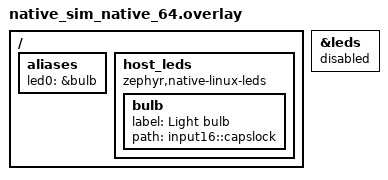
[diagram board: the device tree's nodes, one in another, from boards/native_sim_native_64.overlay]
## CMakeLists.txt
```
#-------------------------------------------------------------------------------
# ZMatter - Matter light bulb on Zephyr
#
# Copyright (c) 2021 Nordic Semiconductor ASA
# SPDX-License-Identifier: Apache-2.0

cmake_minimum_required(VERSION 3.20.0)

# Matter (connectedhomeip) is fetched by west into modules/lib/connectedhomeip.
# Its Zephyr module lives in a sub-directory, so it has to be registered
# explicitly before Zephyr is loaded.
if(NOT DEFINED CHIP_ROOT)
  get_filename_component(CHIP_ROOT $ENV{ZEPHYR_BASE}/../modules/lib/connectedhomeip ABSOLUTE)
endif()
list(APPEND EXTRA_ZEPHYR_MODULES ${CHIP_ROOT}/config/zephyr/chip-module)

# Normally generated by the Matter bootstrap (scripts/activate.sh). It is only
# needed for pigweed's clang toolchain, so an empty file is enough here.
if(NOT EXISTS ${CHIP_ROOT}/build_overrides/pigweed_environment.gni)
  file(WRITE ${CHIP_ROOT}/build_overrides/pigweed_environment.gni "")
endif()

find_package(Zephyr REQUIRED HINTS $ENV{ZEPHYR_BASE})

project(app LANGUAGES C CXX)

# libCHIP.a uses kernel APIs (e.g. k_timer) and is placed after the kernel
# library on the link line; append the kernel archive again after it.
target_link_libraries(chip INTERFACE $<TARGET_FILE:kernel>)

# Application code is C
target_sources(app PRIVATE
  src/main.c
  src/light.c
)
target_sources_ifdef(CONFIG_WIFI_CREDENTIALS_CONNECT_STORED app PRIVATE src/wifi.c)

# C++ shim exposing the Matter C++ API to the C application (src/matter/matter.h)
target_sources(app PRIVATE
  src/matter/matter.cpp
  src/matter/network.cpp
)
target_include_directories(app PRIVATE src)

include(${CHIP_ROOT}/src/app/chip_data_model.cmake)

chip_configure_data_model(app
  ZAP_FILE ${CMAKE_CURRENT_SOURCE_DIR}/light.zap
  ZCL_PATH ${CHIP_ROOT}/src/app/zap-templates/zcl/zcl.json
)

# The code below locates the git index file for this repository and adds it as a dependency for
# the application VERSION file so that if the repo has a new commit added, even if no files in
# the build have changed, the application version file will be regenerated with the new git commit
find_package(Git QUIET)
if(GIT_FOUND)
  execute_process(
    COMMAND ${GIT_EXECUTABLE} rev-parse --absolute-git-dir
    WORKING_DIRECTORY .
    OUTPUT_VARIABLE application_git_dir
    OUTPUT_STRIP_TRAILING_WHITESPACE
    ERROR_STRIP_TRAILING_WHITESPACE
    ERROR_VARIABLE stderr
    RESULT_VARIABLE return_code
  )
  # If there is an error e.g. it is not a git repo, we just silently ignore it and continue
  # without a dependency, this will be the case with freestanding applications.
  if(NOT return_code)
    if(NOT "${stderr}" STREQUAL "")
      message(WARNING "Application build version git rev-parse warned: ${stderr}")
    endif()

    set_property(TARGET app_version_h PROPERTY APP_VERSION_DEPENDS ${application_git_dir}/index)
  endif()
endif()
```

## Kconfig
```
# Copyright (c) 2021 Nordic Semiconductor ASA
# SPDX-License-Identifier: Apache-2.0
#
# This file is the application Kconfig entry point. All application Kconfig
# options can be defined here or included via other application Kconfig files.
# You can browse these options using the west targets menuconfig (terminal) or
# guiconfig (GUI).

menu "Zephyr"
source "Kconfig.zephyr"
endmenu

module = APP
module-str = APP
source "subsys/logging/Kconfig.template.log_config"

if CHIP

# Matter only defines the software version options when the application has
# no VERSION file, so provide them here based on app/VERSION.
config CHIP_DEVICE_SOFTWARE_VERSION
	int "Software version"
	default 1
	range 0 4294967295
	help
	  32-bit software version number exposed in the Basic Information cluster.

config CHIP_DEVICE_SOFTWARE_VERSION_STRING
	string "Software version string"
	default "$(APPVERSION)"
	help
	  Human-readable software version exposed in the Basic Information cluster.

endif # CHIP
```

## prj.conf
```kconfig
# Copyright (c) 2021 Nordic Semiconductor ASA
# SPDX-License-Identifier: Apache-2.0
#
# Matter on/off light bulb for native_sim. Matter runs over the host's
# network interfaces (see README).

# C17 for the application, C++17 for Matter and its wrapper (src/matter)
CONFIG_STD_C17=y
CONFIG_CPP=y
CONFIG_STD_CPP17=y

# Kernel
CONFIG_MAIN_STACK_SIZE=8192
CONFIG_SYSTEM_WORKQUEUE_STACK_SIZE=4096
CONFIG_HEAP_MEM_POOL_SIZE=65536
CONFIG_COMMON_LIBC_MALLOC_ARENA_SIZE=36864
CONFIG_INIT_STACKS=y

# Networking: Zephyr IP stack over the ESP32 Wi-Fi station
# Network Configuration
CONFIG_NETWORKING=y
CONFIG_NET_IPV6=y
CONFIG_NET_IPV6_MLD=y
CONFIG_NET_IPV6_ND=y
CONFIG_NET_IPV6_DAD=y
CONFIG_NET_IPV4=y
CONFIG_NET_DHCPV4=y
CONFIG_NET_UDP=y
CONFIG_NET_SOCKETS=y

CONFIG_NET_IF_UNICAST_IPV6_ADDR_COUNT=6
CONFIG_NET_IF_MCAST_IPV6_ADDR_COUNT=14
CONFIG_NET_MAX_CONTEXTS=10
CONFIG_ZVFS_OPEN_MAX=16

# Wi-Fi statistics, reported by the Matter Wi-Fi diagnostics cluster
CONFIG_NET_STATISTICS=y
CONFIG_NET_STATISTICS_USER_API=y

# Wi-Fi management
CONFIG_NET_MGMT=y
CONFIG_NET_MGMT_EVENT=y
CONFIG_NET_MGMT_EVENT_QUEUE_SIZE=16
CONFIG_NET_MGMT_EVENT_STACK_SIZE=4096

# Wi-Fi Configuration
CONFIG_WIFI=y
CONFIG_WIFI_NM=y

# Bluetooth LE commissioning: the commissioner sends the Wi-Fi credentials
# over BLE, and the device then joins Wi-Fi.
CONFIG_BT=y
CONFIG_BT_PERIPHERAL=y
CONFIG_BT_DEVICE_NAME="ZMatter"
CONFIG_BT_DEVICE_NAME_DYNAMIC=y
CONFIG_BT_DEVICE_NAME_MAX=15
CONFIG_BT_MAX_CONN=1
CONFIG_BT_GATT_DYNAMIC_DB=y
CONFIG_BT_GATT_CACHING=n
# No pairing or bonding: a new random static address is used on every boot
CONFIG_BT_BONDABLE=n
CONFIG_BT_SETTINGS=n

# Large ATT MTU for the Matter BLE transport (BTP)
CONFIG_BT_L2CAP_TX_MTU=247
CONFIG_BT_BUF_ACL_RX_SIZE=251
CONFIG_BT_BUF_ACL_TX_SIZE=251
CONFIG_BT_RX_STACK_SIZE=2048

# Fast connection parameter updates: some commissioners switch to IP quickly
CONFIG_BT_PERIPHERAL_PREF_MIN_INT=36
CONFIG_BT_PERIPHERAL_PREF_MAX_INT=36
CONFIG_BT_PERIPHERAL_PREF_TIMEOUT=500
CONFIG_BT_CONN_PARAM_UPDATE_TIMEOUT=1000

# Enable LED drivers
CONFIG_LED=y

# Persistent storage (backed by the simulated flash, flash.bin)
CONFIG_FLASH=y
CONFIG_FLASH_MAP=y
CONFIG_NVS=y
CONFIG_SETTINGS=y
CONFIG_SETTINGS_NVS=y

# Crypto: PSA API from TF-PSA-Crypto, X.509 from Mbed TLS
CONFIG_MBEDTLS=y
CONFIG_PSA_CRYPTO=y
CONFIG_MBEDTLS_MD_C=y
CONFIG_MBEDTLS_ENTROPY_C=y
CONFIG_MBEDTLS_CTR_DRBG_C=y
CONFIG_ENTROPY_GENERATOR=y

# Matter
CONFIG_CHIP=y
CONFIG_CHIP_WIFI=y
CONFIG_CHIP_ENABLE_PAIRING_AUTOSTART=y
CONFIG_CHIP_CRYPTO_PSA=y
CONFIG_CHIP_OTA_REQUESTOR=n
CONFIG_CHIP_DEVICE_PRODUCT_NAME="ZMatter Light"
CONFIG_CHIP_DEVICE_TYPE=256
CONFIG_CHIP_PROJECT_CONFIG="src/CHIPProjectConfig.h"
CONFIG_OPENTHREAD=n
CONFIG_NET_L2_OPENTHREAD=n
CONFIG_MCUMGR=n
```

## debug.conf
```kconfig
# Copyright (c) 2021 Nordic Semiconductor ASA
# SPDX-License-Identifier: Apache-2.0
#
# This is a Kconfig fragment which can be used to enable debug-related options
# in the application. See the README for more details.

# Logging
CONFIG_LOG=y
CONFIG_NET_LOG=y
CONFIG_LOG_BUFFER_SIZE=8192
CONFIG_LOG_PROCESS_THREAD_STACK_SIZE=4096
CONFIG_LOG_MODE_DEFERRED=y

CONFIG_NET_LOG=y
CONFIG_MATTER_LOG_LEVEL_WRN=y

# Thread stack usage, reported by the Matter diagnostics clusters
CONFIG_THREAD_STACK_INFO=y
CONFIG_STACK_SENTINEL=y
CONFIG_THREAD_ANALYZER=y
CONFIG_THREAD_ANALYZER_AUTO=y
```

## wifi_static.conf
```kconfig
# Copyright (c) 2026 Muhammad Waleed Badar
# SPDX-License-Identifier: Apache-2.0
#
# Join a fixed Wi-Fi network at boot instead of receiving the credentials
# over Bluetooth LE during commissioning. The device is then commissioned
# on-network. Pass the credentials at build time (see README):
#   -DEXTRA_CONF_FILE=wifi_static.conf
#   -DCONFIG_WIFI_CREDENTIALS_STATIC_SSID=\"<ssid>\"
#   -DCONFIG_WIFI_CREDENTIALS_STATIC_PASSWORD=\"<password>\"

# Wi-Fi credentials, connected automatically at boot
CONFIG_WIFI_CREDENTIALS=y
CONFIG_WIFI_CREDENTIALS_STATIC=y
CONFIG_WIFI_CREDENTIALS_BACKEND_SETTINGS=y
CONFIG_WIFI_CREDENTIALS_CONNECT_STORED=y

# No Bluetooth LE commissioning
CONFIG_BT=n
```

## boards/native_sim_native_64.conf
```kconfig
# Copyright (c) 2026 Muhammad Waleed Badar
# SPDX-License-Identifier: Apache-2.0
#
# On native_sim Matter uses the host's sockets directly, so the Zephyr IP
# stack, Wi-Fi and Bluetooth LE from prj.conf are not needed.

# Matter over the host network instead of Wi-Fi
CONFIG_CHIP_ETHERNET=y
CONFIG_CHIP_WIFI=n

# Networking: disables the IP stack, sockets, net_mgmt and net statistics
CONFIG_NETWORKING=n

# Wi-Fi
CONFIG_WIFI=n
CONFIG_WIFI_NM=n

# No Bluetooth controller: commissioned on-network
CONFIG_BT=n
```

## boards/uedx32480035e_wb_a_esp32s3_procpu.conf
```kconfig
# Copyright (c) 2026 Muhammad Waleed Badar
# SPDX-License-Identifier: Apache-2.0
#
# VIEWE UEDX32480035E-WB-A: Matter over Wi-Fi, WS2812 RGB LED as the bulb.
# Wi-Fi and Bluetooth LE are configured in prj.conf and socs/esp32s3_procpu.conf.

# Light bulb: WS2812 RGB LED
CONFIG_LED=n
CONFIG_LED_STRIP=y
```

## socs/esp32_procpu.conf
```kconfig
# Copyright (c) 2026 Muhammad Waleed Badar
# SPDX-License-Identifier: Apache-2.0

# ESP32 related configs
CONFIG_ESP32_WIFI_TASK_STACK_SIZE=4096

# The ESP32 has much less internal RAM than the ESP32-S3: Matter, Wi-Fi and
# Bluetooth LE only fit with smaller heaps and buffer pools (Matter pools: see
# src/CHIPProjectConfig.h).

# Kernel heap, used by the Wi-Fi and Bluetooth controller drivers. The
# drivers ask for 80 KB by default, sized for larger buffer pools.
CONFIG_HEAP_MEM_POOL_IGNORE_MIN=y
CONFIG_HEAP_MEM_POOL_SIZE=40960

# Wi-Fi buffers, allocated from the kernel heap
CONFIG_ESP32_WIFI_STATIC_RX_BUFFER_NUM=6
CONFIG_ESP32_WIFI_DYNAMIC_RX_BUFFER_NUM=16
CONFIG_ESP32_WIFI_DYNAMIC_TX_BUFFER_NUM=16
CONFIG_ESP32_WIFI_AMPDU_TX_ENABLED=n

# IP stack: Matter only uses IPv6
CONFIG_NET_IPV4=n
CONFIG_NET_DHCPV4=n
CONFIG_NET_MAX_CONTEXTS=6
CONFIG_NET_PKT_RX_COUNT=8
CONFIG_NET_PKT_TX_COUNT=8
CONFIG_NET_BUF_RX_COUNT=24
CONFIG_NET_BUF_TX_COUNT=24

# Bluetooth host buffers
CONFIG_BT_BUF_EVT_RX_COUNT=10
CONFIG_BT_BUF_ACL_TX_COUNT=4

# AES lookup tables in flash instead of 8 KB of RAM
CONFIG_MBEDTLS_AES_ROM_TABLES=y
```

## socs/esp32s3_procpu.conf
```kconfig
# Copyright (c) 2026 Muhammad Waleed Badar
# SPDX-License-Identifier: Apache-2.0

# ESP32-S3 related configs
CONFIG_ESP32_WIFI_TASK_STACK_SIZE=4096
```

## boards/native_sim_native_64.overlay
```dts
/*
 * Copyright (c) 2026 Muhammad Waleed Badar
 * SPDX-License-Identifier: Apache-2.0
 *
 * The light bulb is a real LED of the host, driven through
 * /sys/class/leds/<path>/brightness. List the available LEDs with
 * `ls /sys/class/leds` and set `path` accordingly.
 */

/ {
	aliases {
		led0 = &bulb;
	};

	host_leds {
		compatible = "zephyr,native-linux-leds";

		bulb: bulb {
			label = "Light bulb";
			path = "input16::capslock";
		};
	};
};

/* Replaced by the host LED above. */
&leds {
	status = "disabled";
};
```

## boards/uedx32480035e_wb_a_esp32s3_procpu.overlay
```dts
/*
 * Copyright (c) 2026 Muhammad Waleed Badar
 * SPDX-License-Identifier: Apache-2.0
 *
 * VIEWE UEDX32480035E-WB-A: the light bulb is the on-board WS2812 RGB LED
 * (rgb_led, alias led-strip). Matter runs over Wi-Fi.
 */

/ {
	aliases {
		bulb-strip = &rgb_led;
	};
};

&sdhc0 {
	status = "disabled";
};
```

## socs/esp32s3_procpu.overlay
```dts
/*
 * Copyright (c) 2026 Muhammad Waleed Badar
 * SPDX-License-Identifier: Apache-2.0
 */

/ {
	chosen {
		/* Matter state (fabrics, attributes) is kept in the settings */
		zephyr,settings-partition = &storage_partition;
	};
};
```

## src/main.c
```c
/*
 * Copyright (c) 2026 Muhammad Waleed Badar
 * SPDX-License-Identifier: Apache-2.0
 */

#include "light.h"
#include "matter/matter.h"
#include "wifi.h"

#include <zephyr/logging/log.h>

LOG_MODULE_REGISTER(app, CONFIG_APP_LOG_LEVEL);

int main(void)
{
	int err = light_init();

	if (err != 0) {
		LOG_ERR("Light init failed: %d", err);
		return err;
	}

	err = matter_init();
	if (err != 0) {
		return err;
	}

#ifdef CONFIG_WIFI_CREDENTIALS_CONNECT_STORED
	err = wifi_init();
	if (err != 0) {
		return err;
	}
#endif

	LOG_INF("ZMatter light bulb ready (endpoint %u)", LIGHT_ENDPOINT_ID);

	return 0;
}
```

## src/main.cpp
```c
/*
 * Copyright (c) 2026 Muhammad Waleed Badar
 * SPDX-License-Identifier: Apache-2.0
 */

#include "light.h"
#include "wifi.h"

#include <app/server/Server.h>
#include <credentials/DeviceAttestationCredsProvider.h>
#include <credentials/examples/DeviceAttestationCredsExample.h>
#include <data-model-providers/codegen/Instance.h>
#include <lib/support/CHIPMem.h>
#include <platform/CHIPDeviceLayer.h>
#include <platform/Zephyr/DeviceInstanceInfoProviderImpl.h>
#include <setup_payload/OnboardingCodesUtil.h>

#include <zephyr/kernel.h>
#include <zephyr/logging/log.h>

LOG_MODULE_REGISTER(app, CONFIG_APP_LOG_LEVEL);

using namespace chip;
using namespace chip::DeviceLayer;

namespace {

void ChipEventHandler(const ChipDeviceEvent *event, intptr_t /* arg */)
{
	switch (event->Type) {
	case DeviceEventType::kCommissioningComplete:
		LOG_INF("Commissioning complete");
		break;
	case DeviceEventType::kInterfaceIpAddressChanged:
		LOG_INF("IP address changed");
		break;
	default:
		break;
	}
}

#define RETURN_ON_ERROR(expr)                                                                      \
	do {                                                                                       \
		CHIP_ERROR __err = (expr);                                                         \
		if (__err != CHIP_NO_ERROR) {                                                      \
			LOG_ERR("%s failed: %" CHIP_ERROR_FORMAT, #expr, __err.Format());         \
			return __err;                                                              \
		}                                                                                  \
	} while (0)

CHIP_ERROR InitMatter()
{
	RETURN_ON_ERROR(Platform::MemoryInit());
	RETURN_ON_ERROR(PlatformMgr().InitChipStack());

	/* Development credentials only: test DAC and test setup payload. */
	SetDeviceInstanceInfoProvider(&DeviceInstanceInfoProviderMgrImpl());
	Credentials::SetDeviceAttestationCredentialsProvider(
		Credentials::Examples::GetExampleDACProvider());

	static CommonCaseDeviceServerInitParams initParams;
	RETURN_ON_ERROR(initParams.InitializeStaticResourcesBeforeServerInit());
	initParams.dataModelProvider =
		app::CodegenDataModelProviderInstance(initParams.persistentStorageDelegate);
	RETURN_ON_ERROR(Server::GetInstance().Init(initParams));

	ConfigurationMgr().LogDeviceConfig();
	PrintOnboardingCodes(RendezvousInformationFlags(RendezvousInformationFlag::kOnNetwork));

	RETURN_ON_ERROR(PlatformMgr().AddEventHandler(ChipEventHandler, 0));
	RETURN_ON_ERROR(PlatformMgr().StartEventLoopTask());

	return CHIP_NO_ERROR;
}

} // namespace

int main(void)
{
	int err = LightInit();

	if (err) {
		LOG_ERR("Light init failed: %d", err);
		return err;
	}

	if (InitMatter() != CHIP_NO_ERROR) {
		return -1;
	}

#ifdef CONFIG_WIFI_CREDENTIALS_CONNECT_STORED
	if (WifiInit() != 0) {
		return -1;
	}
#endif

	LOG_INF("ZMatter light bulb ready (endpoint %u)", kLightEndpointId);

	return 0;
}
```

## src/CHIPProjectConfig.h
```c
/*
 * Copyright (c) 2026 Muhammad Waleed Badar
 * SPDX-License-Identifier: Apache-2.0
 *
 * Matter project configuration overrides, applied to both the application
 * and the Matter libraries.
 */

#pragma once

/*
 * On native_sim (CONFIG_ARCH_POSIX) Matter talks to the network through the
 * host's BSD sockets, so enumerate the host's interfaces as well instead of
 * the Zephyr ones and join multicast groups with regular socket options.
 */
#ifdef CONFIG_ARCH_POSIX
#define CHIP_SYSTEM_CONFIG_USE_ZEPHYR_NET_IF          0
#define CHIP_SYSTEM_CONFIG_USE_BSD_IFADDRS            1
#define CHIP_SYSTEM_CONFIG_USE_PLATFORM_MULTICAST_API 0
#define IPV6_MULTICAST_IMPLEMENTED

/* Minimal mDNS opens an endpoint per host interface (docker, VPN, ...). */
#define INET_CONFIG_NUM_UDP_ENDPOINTS 32
#endif

/*
 * The ESP32 has much less internal RAM than the ESP32-S3: smaller Matter
 * pools so that Matter, Wi-Fi and Bluetooth LE fit (see
 * socs/esp32_procpu.conf). Three fabrics is below the five that Matter
 * certification requires, which is fine for development.
 */
#ifdef CONFIG_SOC_SERIES_ESP32
#define CHIP_SYSTEM_CONFIG_PACKETBUFFER_POOL_SIZE 6
#define CHIP_CONFIG_MAX_FABRICS                   3
#define CHIP_CONFIG_SECURE_SESSION_POOL_SIZE      8
#define CHIP_CONFIG_MAX_GROUP_DATA_PEERS          4

/*
 * Set along with the default CHIP_CONFIG_MAX_FABRICS in
 * platform/Zephyr/CHIPPlatformConfig.h, so skipped once it is overridden.
 */
#define INET_CONFIG_UDP_SOCKET_MREQN                    1
#define CHIP_SYSTEM_CONFIG_USE_ZEPHYR_SOCKET_EXTENSIONS 0
#endif
```

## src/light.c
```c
/*
 * Copyright (c) 2026 Muhammad Waleed Badar
 * SPDX-License-Identifier: Apache-2.0
 */

#include "light.h"

#include <errno.h>

#include <zephyr/logging/log.h>
#include <zephyr/sys/util.h>

LOG_MODULE_DECLARE(app, CONFIG_APP_LOG_LEVEL);

static bool led_ready;

#if DT_NODE_EXISTS(DT_ALIAS(bulb_strip))

#include <zephyr/drivers/led_strip.h>

/*
 * The bulb: an RGB LED strip (alias bulb-strip), lit white when on, e.g.
 * the WS2812 LED of boards/uedx32480035e_wb_a_esp32s3_procpu.overlay.
 */
static const struct device *const strip = DEVICE_DT_GET(DT_ALIAS(bulb_strip));
static struct led_rgb pixels[DT_PROP(DT_ALIAS(bulb_strip), chain_length)];

/* Full brightness is uncomfortably bright on a bare WS2812. */
#define BULB_LEVEL 0x40U

static int led_write(bool on)
{
	for (size_t i = 0; i < ARRAY_SIZE(pixels); i++) {
		uint8_t level = on ? BULB_LEVEL : 0U;

		pixels[i].r = level;
		pixels[i].g = level;
		pixels[i].b = level;
	}

	return led_strip_update_rgb(strip, pixels, ARRAY_SIZE(pixels));
}

static const char *led_name(void)
{
	return strip->name;
}

static bool led_is_ready(void)
{
	return device_is_ready(strip);
}

#elif DT_NODE_EXISTS(DT_ALIAS(led0))

#include <zephyr/drivers/led.h>

/* The bulb: led0 (on native_sim a host LED, see boards/native_sim_native_64.overlay). */
static const struct led_dt_spec led = LED_DT_SPEC_GET(DT_ALIAS(led0));

static int led_write(bool on)
{
	return on ? led_on_dt(&led) : led_off_dt(&led);
}

static const char *led_name(void)
{
	return led.dev->name;
}

static bool led_is_ready(void)
{
	return led_is_ready_dt(&led);
}

#else

/* No bulb on this board (e.g. esp32_devkitc): the light state is only logged. */
static int led_write(bool on)
{
	ARG_UNUSED(on);

	return -ENODEV;
}

static const char *led_name(void)
{
	return "(none)";
}

static bool led_is_ready(void)
{
	return false;
}

#endif

int light_init(void)
{
	if (!led_is_ready()) {
		/* On native_sim this usually means no write access to the host LED. */
		LOG_WRN("LED %s is not ready, the light state is only logged", led_name());
		return 0;
	}

	led_ready = true;

	return led_write(false);
}

void light_set(bool on)
{
	if (led_ready) {
		int err = led_write(on);

		if (err != 0) {
			LOG_ERR("Failed to set LED: %d", err);
		}
	}

	LOG_INF("Light is %s", on ? "ON" : "OFF");
}
```

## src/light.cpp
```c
/*
 * Copyright (c) 2026 Muhammad Waleed Badar
 * SPDX-License-Identifier: Apache-2.0
 */

#include "light.h"

#include <app-common/zap-generated/attributes/Accessors.h>
#include <app-common/zap-generated/ids/Attributes.h>
#include <app-common/zap-generated/ids/Clusters.h>
#include <app/ConcreteAttributePath.h>
#include <app/util/generic-callbacks.h>

#include <zephyr/logging/log.h>

LOG_MODULE_DECLARE(app, CONFIG_APP_LOG_LEVEL);

using namespace chip;
using namespace chip::app::Clusters;

static bool sLedReady;

#if DT_NODE_EXISTS(DT_ALIAS(bulb_strip))

#include <zephyr/drivers/led_strip.h>

/*
 * The bulb: an RGB LED strip (alias bulb-strip), lit white when on, e.g.
 * the WS2812 LED of boards/uedx32480035e_wb_a_esp32s3_procpu.overlay.
 */
static const struct device *const sStrip = DEVICE_DT_GET(DT_ALIAS(bulb_strip));
static struct led_rgb sPixels[DT_PROP(DT_ALIAS(bulb_strip), chain_length)];

/* Full brightness is uncomfortably bright on a bare WS2812. */
#define BULB_LEVEL 0x40

static int LedWrite(bool on)
{
	for (struct led_rgb &pixel : sPixels) {
		pixel.r = pixel.g = pixel.b = on ? BULB_LEVEL : 0;
	}

	return led_strip_update_rgb(sStrip, sPixels, ARRAY_SIZE(sPixels));
}

static const char *LedName(void)
{
	return sStrip->name;
}

static bool LedIsReady(void)
{
	return device_is_ready(sStrip);
}

#else

#include <zephyr/drivers/led.h>

/* The bulb: led0 (on native_sim a host LED, see boards/native_sim_native_64.overlay). */
static const struct led_dt_spec sLed = LED_DT_SPEC_GET(DT_ALIAS(led0));

static int LedWrite(bool on)
{
	return on ? led_on_dt(&sLed) : led_off_dt(&sLed);
}

static const char *LedName(void)
{
	return sLed.dev->name;
}

static bool LedIsReady(void)
{
	return led_is_ready_dt(&sLed);
}

#endif

int LightInit(void)
{
	if (!LedIsReady()) {
		/* On native_sim this usually means no write access to the host LED. */
		LOG_WRN("LED %s is not ready, the light state is only logged", LedName());
		return 0;
	}

	sLedReady = true;

	return LedWrite(false);
}

static void LightSet(bool on)
{
	if (sLedReady) {
		int err = LedWrite(on);

		if (err) {
			LOG_ERR("Failed to set LED: %d", err);
		}
	}

	LOG_INF("Light is %s", on ? "ON" : "OFF");
}

void MatterPostAttributeChangeCallback(const app::ConcreteAttributePath &path, uint8_t type,
				       uint16_t size, uint8_t *value)
{
	if (path.mEndpointId == kLightEndpointId && path.mClusterId == OnOff::Id &&
	    path.mAttributeId == OnOff::Attributes::OnOff::Id) {
		LightSet(*value != 0);
	}
}

/* Restore the light from the persisted OnOff attribute at boot. */
void emberAfOnOffClusterInitCallback(EndpointId endpoint)
{
	bool on = false;

	if (endpoint != kLightEndpointId) {
		return;
	}

	if (OnOff::Attributes::OnOff::Get(endpoint, &on) == Protocols::InteractionModel::Status::Success) {
		LightSet(on);
	}
}
```

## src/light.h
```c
/*
 * Copyright (c) 2026 Muhammad Waleed Badar
 * SPDX-License-Identifier: Apache-2.0
 */

#pragma once

#include <stdbool.h>

#ifdef __cplusplus
extern "C" {
#endif

/* Endpoint hosting the On/Off Light device type (see light.zap). */
#define LIGHT_ENDPOINT_ID 1

/* Configure the LED that represents the bulb (alias bulb-strip, else led0). */
int light_init(void);

/* Turn the bulb on or off. */
void light_set(bool on);

#ifdef __cplusplus
}
#endif
```

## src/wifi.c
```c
/*
 * Copyright (c) 2026 Muhammad Waleed Badar
 * SPDX-License-Identifier: Apache-2.0
 */

#include "wifi.h"

#include <zephyr/kernel.h>
#include <zephyr/logging/log.h>
#include <zephyr/net/net_if.h>
#include <zephyr/net/net_mgmt.h>
#include <zephyr/net/wifi_mgmt.h>

LOG_MODULE_DECLARE(app, CONFIG_APP_LOG_LEVEL);

/* Delay before retrying after a disconnect or a failed connect */
#define WIFI_RECONNECT_DELAY K_SECONDS(5)

static struct k_work_delayable reconnect_work;
static struct net_mgmt_event_callback wifi_mgmt_cb;

/* Start joining the network from the stored (build-time) credentials. */
static int wifi_connect(void)
{
	struct net_if *iface = net_if_get_wifi_sta();
	int ret;

	if (iface == NULL) {
		LOG_ERR("No Wi-Fi STA interface");
		return -ENODEV;
	}

	ret = net_mgmt(NET_REQUEST_WIFI_CONNECT_STORED, iface, NULL, 0);
	if (ret != 0) {
		LOG_ERR("Connect stored failed: %d", ret);
		return ret;
	}

	LOG_INF("Connecting to WLAN");

	return 0;
}

static void reconnect_handler(struct k_work *work)
{
	ARG_UNUSED(work);

	if (wifi_connect() != 0) {
		(void)k_work_reschedule(&reconnect_work, WIFI_RECONNECT_DELAY);
	}
}

static void wifi_event_handler(struct net_mgmt_event_callback *cb, uint64_t mgmt_event,
			       struct net_if *iface)
{
	const struct wifi_status *status = (const struct wifi_status *)cb->info;

	ARG_UNUSED(iface);

	switch (mgmt_event) {
	case NET_EVENT_WIFI_CONNECT_RESULT:
		if (status->status != 0) {
			LOG_WRN("Wi-Fi connect failed (%d), retrying", status->status);
			(void)k_work_reschedule(&reconnect_work, WIFI_RECONNECT_DELAY);
		} else {
			LOG_INF("Wi-Fi connected");
			(void)k_work_cancel_delayable(&reconnect_work);
		}
		break;
	case NET_EVENT_WIFI_DISCONNECT_RESULT:
		LOG_WRN("Wi-Fi disconnected (reason %d), reconnecting", status->disconn_reason);
		(void)k_work_reschedule(&reconnect_work, WIFI_RECONNECT_DELAY);
		break;
	default:
		break;
	}
}

int wifi_init(void)
{
	int ret;

	k_work_init_delayable(&reconnect_work, reconnect_handler);

	net_mgmt_init_event_callback(&wifi_mgmt_cb, wifi_event_handler,
				     NET_EVENT_WIFI_CONNECT_RESULT |
					     NET_EVENT_WIFI_DISCONNECT_RESULT);
	net_mgmt_add_event_callback(&wifi_mgmt_cb);

	/* First attempt runs from the work queue, like every retry. */
	ret = k_work_schedule(&reconnect_work, K_NO_WAIT);

	return (ret < 0) ? ret : 0;
}
```

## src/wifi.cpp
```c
/*
 * Copyright (c) 2026 Muhammad Waleed Badar
 * SPDX-License-Identifier: Apache-2.0
 */

#include "wifi.h"

#include <zephyr/kernel.h>
#include <zephyr/logging/log.h>
#include <zephyr/net/net_if.h>
#include <zephyr/net/net_mgmt.h>
#include <zephyr/net/wifi_mgmt.h>

LOG_MODULE_DECLARE(app, CONFIG_APP_LOG_LEVEL);

/* Delay before retrying after a disconnect or a failed connect */
#define WIFI_RECONNECT_DELAY K_SECONDS(5)

static struct k_work_delayable sReconnectWork;
static struct net_mgmt_event_callback sWifiMgmtCb;

/* Start joining the network from the stored (build-time) credentials. */
static int WifiConnect(void)
{
	struct net_if *iface = net_if_get_wifi_sta();
	int ret;

	if (iface == NULL) {
		LOG_ERR("No Wi-Fi STA interface");
		return -ENODEV;
	}

	ret = net_mgmt(NET_REQUEST_WIFI_CONNECT_STORED, iface, NULL, 0);
	if (ret != 0) {
		LOG_ERR("Connect stored failed: %d", ret);
		return ret;
	}

	LOG_INF("Connecting to WLAN");

	return 0;
}

static void ReconnectHandler(struct k_work *work)
{
	ARG_UNUSED(work);

	if (WifiConnect() != 0) {
		k_work_reschedule(&sReconnectWork, WIFI_RECONNECT_DELAY);
	}
}

static void WifiEventHandler(struct net_mgmt_event_callback *cb, uint64_t mgmt_event,
			     struct net_if *iface)
{
	const struct wifi_status *status = (const struct wifi_status *)cb->info;

	ARG_UNUSED(iface);

	switch (mgmt_event) {
	case NET_EVENT_WIFI_CONNECT_RESULT:
		if (status->status != 0) {
			LOG_WRN("Wi-Fi connect failed (%d), retrying", status->status);
			k_work_reschedule(&sReconnectWork, WIFI_RECONNECT_DELAY);
		} else {
			LOG_INF("Wi-Fi connected");
			k_work_cancel_delayable(&sReconnectWork);
		}
		break;
	case NET_EVENT_WIFI_DISCONNECT_RESULT:
		LOG_WRN("Wi-Fi disconnected (reason %d), reconnecting", status->disconn_reason);
		k_work_reschedule(&sReconnectWork, WIFI_RECONNECT_DELAY);
		break;
	default:
		break;
	}
}

int WifiInit(void)
{
	k_work_init_delayable(&sReconnectWork, ReconnectHandler);

	net_mgmt_init_event_callback(&sWifiMgmtCb, WifiEventHandler,
				     NET_EVENT_WIFI_CONNECT_RESULT |
					     NET_EVENT_WIFI_DISCONNECT_RESULT);
	net_mgmt_add_event_callback(&sWifiMgmtCb);

	/* First attempt runs from the work queue, like every retry. */
	k_work_schedule(&sReconnectWork, K_NO_WAIT);

	return 0;
}
```

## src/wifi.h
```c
/*
 * Copyright (c) 2026 Muhammad Waleed Badar
 * SPDX-License-Identifier: Apache-2.0
 */

#pragma once

#ifdef __cplusplus
extern "C" {
#endif

/*
 * Join the Wi-Fi network from the stored credentials, and reconnect from a
 * work item whenever the link drops or a connect attempt fails.
 */
int wifi_init(void);

#ifdef __cplusplus
}
#endif
```
